# RockChip_RK3588 register map
Vendor: RockChip Electronics Co., Ltd.; Series: RK3588; File version: 0.1
Registers are 32-bit, read-write, no defined reset value unless marked. A register's access mark holds for its fields unless they carry their own. Offsets are from the block's base; [hi:lo] are bit positions; {n}, {i} and the like mark numbered series; 'fields as' and 'values as' point back to an identical list.

## CRU (part 5 of 6)
Base 0xFD7C0000
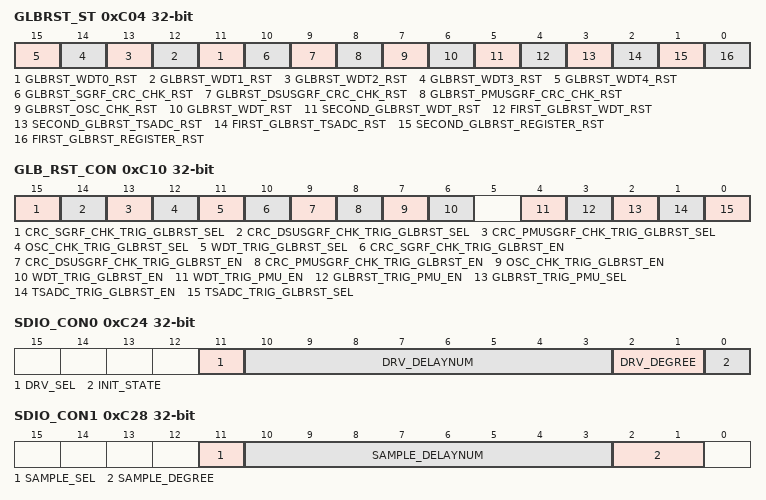
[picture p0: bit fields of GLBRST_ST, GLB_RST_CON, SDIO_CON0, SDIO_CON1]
0xC04 GLBRST_ST — System control register
  [n+11] GLBRST_WDT{n}_RST (n=0..4) — glbrst_wdt{n}_rst If High, global reset by WDT{n}.
  [10] GLBRST_SGRF_CRC_CHK_RST — glbrst_sgrf_crc_chk_rst If High, global reset by SGRF_CRC check.
  [9] GLBRST_DSUSGRF_CRC_CHK_RST — glbrst_dsusgrf_crc_chk_rst If High, global reset by DSUSGRF_CRC check.
  [8] GLBRST_PMUSGRF_CRC_CHK_RST — glbrst_pmusgrf_crc_chk_rst If High, global reset by PMUSGRF_CRC check.
  [7] GLBRST_OSC_CHK_RST — glbrst_osc_chk_rst If High, global reset by OSC check.
  [6] GLBRST_WDT_RST — glbrst_wdt_rst If High, global reset by WDT. Check CRU_GLBRST_ST[15:11] for detail.
  [5] SECOND_GLBRST_WDT_RST — second_glbrst_wdt_rst If High, second global reset by WDT.
  [4] FIRST_GLBRST_WDT_RST — first_glbrst_wdt_rst If High, first global reset by WDT.
  [3] SECOND_GLBRST_TSADC_RST — second_glbrst_tsadc_rst If High, second global reset by TSADC.
  [2] FIRST_GLBRST_TSADC_RST — first_glbrst_tsadc_rst If High, first global reset by TSADC.
  [1] SECOND_GLBRST_REGISTER_RST — second_glbrst_register_rst If High, second global reset by register.
  [0] FIRST_GLBRST_REGISTER_RST — first_glbrst_register_rst If High, first global reset by register.
0xC08 GLB_SRST_FST_VALUE — System control register
  [15:0] GLB_SRSC_FIRST_VALUE — GLB_SRST_FST The first global software reset configuration value. Set 0xfdb9 enable.
0xC0C GLB_SRST_SND_VALUE — System control register
  [15:0] GLB_SRSC_SECOND_VALUE — GLB_SRST_SND The second global software reset configuration value. Set 0xeca8 enable.
0xC10 GLB_RST_CON — System control register
  [15] CRC_SGRF_CHK_TRIG_GLBRST_SEL
    1=FIRST (CRC_SGRF check trigger first global reset.); 0=SECOND (CRC_SGRF check trigger second global reset.)
  [14] CRC_DSUSGRF_CHK_TRIG_GLBRST_SEL
    1=FIRST (CRC_DSUSGRF check trigger first global reset.); 0=SECOND (CRC_DSUSGRF check trigger second global reset.)
  [13] CRC_PMUSGRF_CHK_TRIG_GLBRST_SEL
    1=FIRST (CRC_PMUSGRF check trigger first global reset.); 0=SECOND (CRC_PMUSGRF check trigger second global reset.)
  [12] OSC_CHK_TRIG_GLBRST_SEL
    1=FIRST (OSC check trigger first global reset.); 0=SECOND (OSC check trigger second global reset.)
  [11] WDT_TRIG_GLBRST_SEL
    1=FIRST (WDT trigger first global reset.); 0=SECOND (WDT trigger second global reset.)
  [10] CRC_SGRF_CHK_TRIG_GLBRST_EN
    1=ENABLE (Enable CRC_SGRF check trigger global reset.); 0=DISABLE (Disable CRC_SGRF check trigger global reset.)
  [9] CRC_DSUSGRF_CHK_TRIG_GLBRST_EN
    1=ENABLE (Enable CRC_DSUSGRF check trigger global reset.); 0=DISABLE (Disable CRC_DSUSGRF check trigger global reset.)
  [8] CRC_PMUSGRF_CHK_TRIG_GLBRST_EN
    1=ENABLE (Enable CRC_PMUSGRF check trigger global reset.); 0=DISABLE (Disable CRC_PMUSGRF check trigger global reset.)
  [7] OSC_CHK_TRIG_GLBRST_EN
    1=ENABLE (Enable OSC check trigger global reset.); 0=DISABLE (Disable OSC check trigger global reset.)
  [6] WDT_TRIG_GLBRST_EN
    1=ENABLE (Enable WDT trigger global reset.); 0=DISABLE (Disable WDT trigger global reset.)
  [4] WDT_TRIG_PMU_EN
    1=ENABLE (Enable wdt reset trigger pmu reset.); 0=DISABLE (Disable wdt reset trigger pmu reset.)
  [3] GLBRST_TRIG_PMU_EN
    1=ENABLE (Enable global reset trigger pmu reset.); 0=DISABLE (Disable global reset trigger pmu reset.)
  [2] GLBRST_TRIG_PMU_SEL
    1=FIRST (First global reset trigger pmu reset.); 0=SECOND (Second global reset trigger pmu reset.)
  [1] TSADC_TRIG_GLBRST_EN
    1=ENABLE (Enable tsadc trigger global reset.); 0=DISABLE (Disable tsadc trigger global reset.)
  [0] TSADC_TRIG_GLBRST_SEL
    1=FIRST (tsadc trigger first global reset.); 0=SECOND (tsadc trigger second global reset.)
0xC24 SDIO_CON0 — System control register
  [11] DRV_SEL — Selection for drive clock
    0=PHASE (Select clock delayed by phase shift); 1=PHASE_AND_DELAY (Select clock delayed by phase shift and delay line It can be modified when init_state=1 and should be stable when init_state=0.)
  [10:3] DRV_DELAYNUM — Delay element number configuration for drive clock. It can be modified when init_state=1 and should be stable when init_state=0.
  [2:1] DRV_DEGREE — Phase selection for drive clock. It can be modified when init_state=1 and should be stable when init_state=0.
    0=DEGREE_0; 1=DEGREE_90; 2=DEGREE_180; 3=DEGREE_270
  [0] INIT_STATE — Enable initialization for clock source. When init_state=1, the host clocks including drive clock and sample clock are inactive.
    0=DISABLE; 1=ENABLE
0xC28 SDIO_CON1 — System control register
  [11] SAMPLE_SEL — Selection for sample clock. It can be modified when init_state=1 and should be stable when init_state=0.
    0=PHASE (Select clock delayed by phase shift); 1=PHASE_AND_DELAY (Select clock delayed by phase shift and delay line)
  [10:3] SAMPLE_DELAYNUM — Delay element number configuration for sample clock. It can be modified when init_state=1 and should be stable when init_state=0.
  [2:1] SAMPLE_DEGREE — Phase selection for sample clock. It can be modified when init_state=1 and should be stable when init_state=0.
    0=DEGREE_0; 1=DEGREE_90; 2=DEGREE_180; 3=DEGREE_270
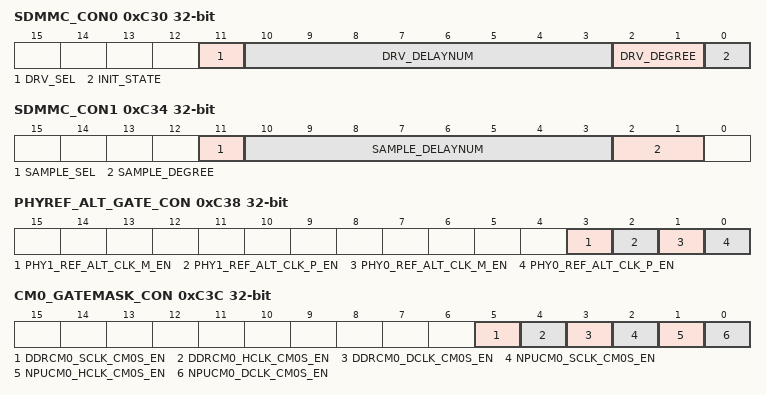
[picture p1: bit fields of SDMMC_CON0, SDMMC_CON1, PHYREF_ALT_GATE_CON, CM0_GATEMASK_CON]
0xC30 SDMMC_CON0 — System control register
  [11] DRV_SEL — Selection for drive clock. It can be modified when init_state=1 and should be stable when init_state=0.
    values as SDIO_CON1.SAMPLE_SEL
  [10:3] DRV_DELAYNUM — Delay element number configuration for drive clock. It can be modified when init_state=1 and should be stable when init_state=0.
  [2:1] DRV_DEGREE — Phase selection for drive clock. It can be modified when init_state=1 and should be stable when init_state=0.
    0=DEGREE_0; 1=DEGREE_90; 2=DEGREE_180; 3=DEGREE_270
  [0] INIT_STATE — Enable initialization for clock source. When init_state=1, the host clocks including drive clock and sample clock are inactive.
    0=DISABLE; 1=ENABLE
0xC34 SDMMC_CON1 — System control register
  fields as SDIO_CON1
0xC38 PHYREF_ALT_GATE_CON — System control register
  [all] fields
    1=DISABLE; 0=ENABLE
  [3] PHY1_REF_ALT_CLK_M_EN — phy1_ref_alt_clk_m clock gating control. When high, disable clock.
  [2] PHY1_REF_ALT_CLK_P_EN — phy1_ref_alt_clk_p clock gating control. When high, disable clock.
  [1] PHY0_REF_ALT_CLK_M_EN — phy0_ref_alt_clk_m clock gating control. When high, disable clock.
  [0] PHY0_REF_ALT_CLK_P_EN — phy0_ref_alt_clk_p clock gating control. When high, disable clock.
0xC3C CM0_GATEMASK_CON — System control register
  [all] fields
    1=DISABLE; 0=ENABLE
  [5] DDRCM0_SCLK_CM0S_EN — ddrcm0_sclk_cm0s clock gating control. When high, disable clock.
  [4] DDRCM0_HCLK_CM0S_EN — ddrcm0_hclk_cm0s clock gating control. When high, disable clock.
  [3] DDRCM0_DCLK_CM0S_EN — ddrcm0_dclk_cm0s clock gating control. When high, disable clock.
  [2] NPUCM0_SCLK_CM0S_EN — npucm0_sclk_cm0s clock gating control. When high, disable clock.
  [1] NPUCM0_HCLK_CM0S_EN — npucm0_hclk_cm0s clock gating control. When high, disable clock.
  [0] NPUCM0_DCLK_CM0S_EN — npucm0_dclk_cm0s clock gating control. When high, disable clock.
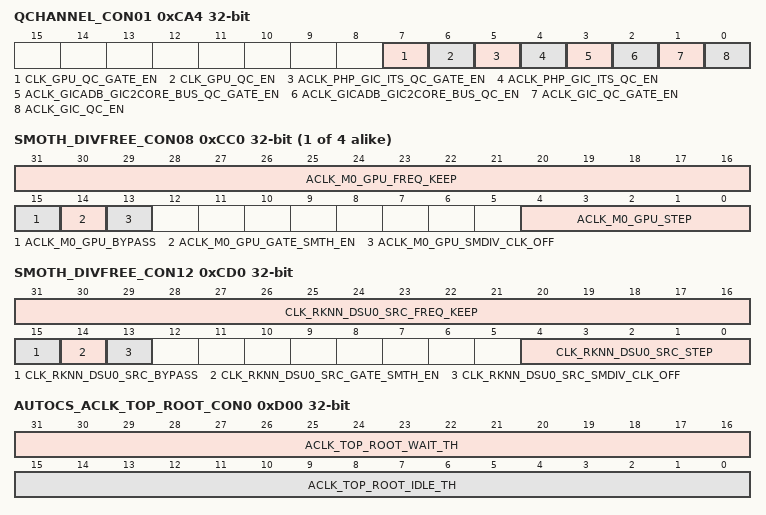
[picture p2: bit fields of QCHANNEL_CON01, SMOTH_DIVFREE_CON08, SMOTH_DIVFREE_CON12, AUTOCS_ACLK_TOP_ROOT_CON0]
0xCA4 QCHANNEL_CON01 — Qchannel control register 1
  [7] CLK_GPU_QC_GATE_EN — qc_gate_en
    1=DOC_BUG_ENABLE (Enable clk_gpu qchannel gate function.); 0=DOC_BUG_DISABLE (Disable clk_gpu qchannel gate function.)
  [6] CLK_GPU_QC_EN — qc_en
    1=DOC_BUG_ENABLE (Enable clk_gpu qchannel.); 0=DOC_BUG_DISABLE (Disable clk_gpu qchannel.)
  [5] ACLK_PHP_GIC_ITS_QC_GATE_EN — qc_gate_en
    1=DOC_BUG_ENABLE (Enable aclk_php_gic_its qchannel gate function.); 0=DOC_BUG_DISABLE (Disable aclk_php_gic_its qchannel gate function.)
  [4] ACLK_PHP_GIC_ITS_QC_EN — qc_en
    1=DOC_BUG_ENABLE (Enable aclk_php_gic_its qchannel.); 0=DOC_BUG_DISABLE (Disable aclk_php_gic_its qchannel.)
  [3] ACLK_GICADB_GIC2CORE_BUS_QC_GATE_EN — qc_gate_en
    1=DOC_BUG_ENABLE (Enable aclk_gicadb_gic2core_bus qchannel gate function.); 0=DOC_BUG_DISABLE (Disable aclk_gicadb_gic2core_bus qchannel gate function.)
  [2] ACLK_GICADB_GIC2CORE_BUS_QC_EN — qc_en
    1=DOC_BUG_ENABLE (Enable aclk_gicadb_gic2core_bus qchannel.); 0=DOC_BUG_DISABLE (Disable aclk_gicadb_gic2core_bus qchannel.)
  [1] ACLK_GIC_QC_GATE_EN — qc_gate_en
    1=DOC_BUG_ENABLE (Enable aclk_gic qchannel gate function.); 0=DOC_BUG_DISABLE (Disable aclk_gic qchannel gate function.)
  [0] ACLK_GIC_QC_EN — qc_en
    1=DOC_BUG_ENABLE (Enable aclk_gic qchannel.); 0=DOC_BUG_DISABLE (Disable aclk_gic qchannel.)
{0xCA0+4i} SMOTH_DIVFREE_CON{i:02} (i=8..11) — Smoothdiv control register
  [31:16] ACLK_M{i-8}_GPU_FREQ_KEEP — freq_keep Cycles to keep every step.
  [15] ACLK_M{i-8}_GPU_BYPASS — bypass Division signal bypass.
    1=BYPASS; 0=USE (Use Smoothdiv to control clock division.)
  [14] ACLK_M{i-8}_GPU_GATE_SMTH_EN — gate_smth_en If trigger smoothdiv function when clk been gated.
    1=ENABLE; 0=DISABLE
  [13] ACLK_M{i-8}_GPU_SMDIV_CLK_OFF — smdiv_clk_off Turn off smoothdiv module clk.
    1=TURN_OFF; 0=TURN_ON
  [4:0] ACLK_M{i-8}_GPU_STEP — step Step of div from 0x1f to setting configuration.
0xCD0 SMOTH_DIVFREE_CON12 — Smoothdiv control register
  [31:16] CLK_RKNN_DSU0_SRC_FREQ_KEEP — freq_keep Cycles to keep every step.
  [15] CLK_RKNN_DSU0_SRC_BYPASS — bypass Division signal bypass.
    1=BYPASS; 0=USE (Use Smoothdiv to control clock division.)
  [14] CLK_RKNN_DSU0_SRC_GATE_SMTH_EN — gate_smth_en If trigger smoothdiv function when clk been gated.
    1=ENABLE; 0=DISABLE
  [13] CLK_RKNN_DSU0_SRC_SMDIV_CLK_OFF — smdiv_clk_off Turn off smoothdiv module clk.
    1=TURN_OFF; 0=TURN_ON
  [4:0] CLK_RKNN_DSU0_SRC_STEP — step Step of div from 0x1f to setting configuration.
0xD00 AUTOCS_ACLK_TOP_ROOT_CON0 — Auto clock switch control register 0
  [31:16] ACLK_TOP_ROOT_WAIT_TH — wait_th. Wait time threshold, measured by original clk.
  [15:0] ACLK_TOP_ROOT_IDLE_TH — idle_th. Idle time threshold, measured by original clk.
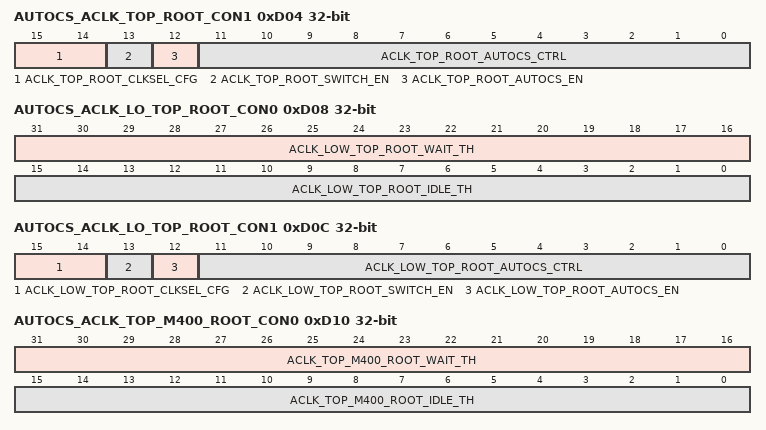
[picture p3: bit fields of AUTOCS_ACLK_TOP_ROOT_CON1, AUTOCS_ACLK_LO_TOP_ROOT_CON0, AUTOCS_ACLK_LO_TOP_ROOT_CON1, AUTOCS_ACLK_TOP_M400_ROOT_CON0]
0xD04 AUTOCS_ACLK_TOP_ROOT_CON1 — Auto clock switch control register 1
  [15:14] ACLK_TOP_ROOT_CLKSEL_CFG — clksel_cfg Auto switch clock selection.
    0=ORIGINAL_CLK; 1=XIN_OSC0_FUNC_DIV; 2=CLK_RTC_32K
  [13] ACLK_TOP_ROOT_SWITCH_EN — switch_en
    1=ENABLE (Enable aclk_top_root switched to lower frequency when module is inactive.); 0=DISABLE (Disable auto switch function.)
  [12] ACLK_TOP_ROOT_AUTOCS_EN — autocs_en
    1=ENABLE (Enable aclk_top_root switch to lower frequency.); 0=DISABLE
  [11:0] ACLK_TOP_ROOT_AUTOCS_CTRL — autocs_ctrl. Others: Reserved.
    0xFFF=ENABLE (Enable aclk_top_root switch to lower frequency.); 0=DISABLE
0xD08 AUTOCS_ACLK_LO_TOP_ROOT_CON0 — Auto clock switch control register 0
  [31:16] ACLK_LOW_TOP_ROOT_WAIT_TH — wait_th. Wait time threshold, measured by original clk.
  [15:0] ACLK_LOW_TOP_ROOT_IDLE_TH — idle_th. Idle time threshold, measured by original clk.
0xD0C AUTOCS_ACLK_LO_TOP_ROOT_CON1 — Auto clock switch control register 1
  [15:14] ACLK_LOW_TOP_ROOT_CLKSEL_CFG — clksel_cfg Auto switch clock selection.
    0=ORIGINAL_CLK; 1=XIN_OSC0_FUNC_DIV; 2=CLK_RTC_32K
  [13] ACLK_LOW_TOP_ROOT_SWITCH_EN — switch_en
    1=ENABLE (Enable aclk_low_top_root switched to lower frequency when module is inactive.); 0=DISABLE (Disable auto switch function.)
  [12] ACLK_LOW_TOP_ROOT_AUTOCS_EN — autocs_en
    1=ENABLE (Enable aclk_low_top_root switch to lower frequency.); 0=DISABLE
  [11:0] ACLK_LOW_TOP_ROOT_AUTOCS_CTRL — autocs_ctrl. Others: Reserved.
    0xFFF=ENABLE (Enable aclk_low_top_root switch to lower frequency.); 0=DISABLE
0xD10 AUTOCS_ACLK_TOP_M400_ROOT_CON0 — Auto clock switch control register 0
  [31:16] ACLK_TOP_M400_ROOT_WAIT_TH — wait_th. Wait time threshold, measured by original clk.
  [15:0] ACLK_TOP_M400_ROOT_IDLE_TH — idle_th. Idle time threshold, measured by original clk.
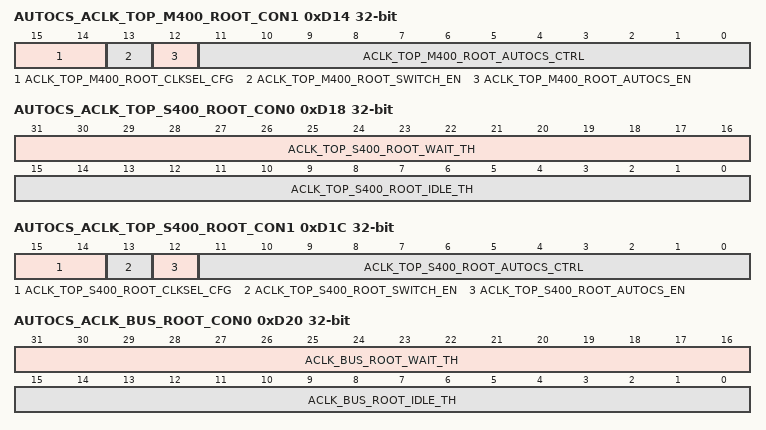
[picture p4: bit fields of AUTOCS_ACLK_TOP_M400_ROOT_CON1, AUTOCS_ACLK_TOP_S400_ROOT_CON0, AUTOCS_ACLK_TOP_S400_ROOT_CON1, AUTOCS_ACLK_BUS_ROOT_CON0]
0xD14 AUTOCS_ACLK_TOP_M400_ROOT_CON1 — Auto clock switch control register 1
  [15:14] ACLK_TOP_M400_ROOT_CLKSEL_CFG — clksel_cfg Auto switch clock selection.
    0=ORIGINAL_CLK; 1=XIN_OSC0_FUNC_DIV; 2=CLK_RTC_32K
  [13] ACLK_TOP_M400_ROOT_SWITCH_EN — switch_en
    1=ENABLE (Enable aclk_top_m400_root switched to lower frequency when module is inactive.); 0=DISABLE (Disable auto switch function.)
  [12] ACLK_TOP_M400_ROOT_AUTOCS_EN — autocs_en
    1=ENABLE (Enable aclk_top_m400_root switch to lower frequency.); 0=DISABLE
  [11:0] ACLK_TOP_M400_ROOT_AUTOCS_CTRL — autocs_ctrl. Others: Reserved.
    0xFFF=ENABLE (Enable aclk_top_m400_root switch to lower frequency.); 0=DISABLE
0xD18 AUTOCS_ACLK_TOP_S400_ROOT_CON0 — Auto clock switch control register 0
  [31:16] ACLK_TOP_S400_ROOT_WAIT_TH — wait_th. Wait time threshold, measured by original clk.
  [15:0] ACLK_TOP_S400_ROOT_IDLE_TH — idle_th. Idle time threshold, measured by original clk.
0xD1C AUTOCS_ACLK_TOP_S400_ROOT_CON1 — Auto clock switch control register 1
  [15:14] ACLK_TOP_S400_ROOT_CLKSEL_CFG — clksel_cfg Auto switch clock selection.
    0=ORIGINAL_CLK; 1=XIN_OSC0_FUNC_DIV; 2=CLK_RTC_32K
  [13] ACLK_TOP_S400_ROOT_SWITCH_EN — switch_en
    1=ENABLE (Enable aclk_top_s400_root switched to lower frequency when module is inactive.); 0=DISABLE (Disable auto switch function.)
  [12] ACLK_TOP_S400_ROOT_AUTOCS_EN — autocs_en
    1=ENABLE (Enable aclk_top_s400_root switch to lower frequency.); 0=DISABLE
  [11:0] ACLK_TOP_S400_ROOT_AUTOCS_CTRL — autocs_ctrl. Others: Reserved.
    0xFFF=ENABLE (Enable aclk_top_s400_root switch to lower frequency.); 0=DISABLE
0xD20 AUTOCS_ACLK_BUS_ROOT_CON0 — Auto clock switch control register 0
  [31:16] ACLK_BUS_ROOT_WAIT_TH — wait_th. Wait time threshold, measured by original clk.
  [15:0] ACLK_BUS_ROOT_IDLE_TH — idle_th. Idle time threshold, measured by original clk.
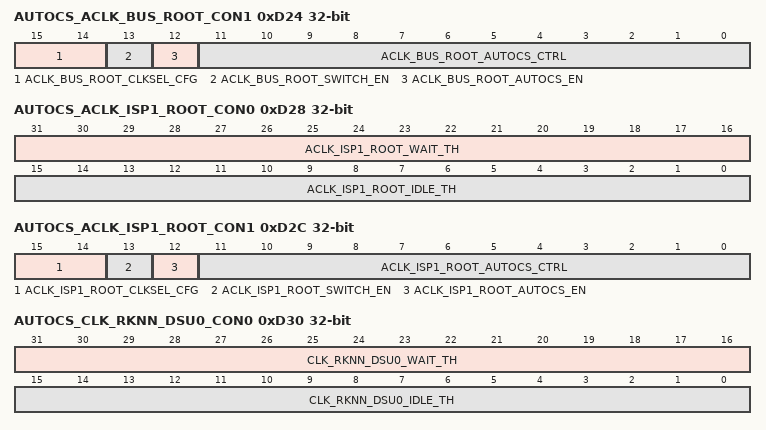
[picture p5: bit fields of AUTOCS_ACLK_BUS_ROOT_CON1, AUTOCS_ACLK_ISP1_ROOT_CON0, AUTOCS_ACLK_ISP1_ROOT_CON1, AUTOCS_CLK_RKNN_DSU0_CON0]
0xD24 AUTOCS_ACLK_BUS_ROOT_CON1 — Auto clock switch control register 1
  [15:14] ACLK_BUS_ROOT_CLKSEL_CFG — clksel_cfg Auto switch clock selection.
    0=ORIGINAL_CLK; 1=XIN_OSC0_FUNC_DIV; 2=CLK_RTC_32K
  [13] ACLK_BUS_ROOT_SWITCH_EN — switch_en
    1=ENABLE (Enable aclk_bus_root switched to lower frequency when module is inactive.); 0=DISABLE (Disable auto switch function.)
  [12] ACLK_BUS_ROOT_AUTOCS_EN — autocs_en
    1=ENABLE (Enable aclk_bus_root switch to lower frequency.); 0=DISABLE
  [11:0] ACLK_BUS_ROOT_AUTOCS_CTRL — autocs_ctrl. Others: Reserved.
    0xFFF=ENABLE (Enable aclk_bus_root switch to lower frequency.); 0=DISABLE
0xD28 AUTOCS_ACLK_ISP1_ROOT_CON0 — Auto clock switch control register 0
  [31:16] ACLK_ISP1_ROOT_WAIT_TH — wait_th. Wait time threshold, measured by original clk.
  [15:0] ACLK_ISP1_ROOT_IDLE_TH — idle_th. Idle time threshold, measured by original clk.
0xD2C AUTOCS_ACLK_ISP1_ROOT_CON1 — Auto clock switch control register 1
  [15:14] ACLK_ISP1_ROOT_CLKSEL_CFG — clksel_cfg Auto switch clock selection.
    0=ORIGINAL_CLK; 1=XIN_OSC0_FUNC_DIV; 2=CLK_RTC_32K
  [13] ACLK_ISP1_ROOT_SWITCH_EN — switch_en
    1=ENABLE (Enable aclk_isp1_root switched to lower frequency when module is inactive.); 0=DISABLE (Disable auto switch function.)
  [12] ACLK_ISP1_ROOT_AUTOCS_EN — autocs_en
    1=ENABLE (Enable aclk_isp1_root switch to lower frequency.); 0=DISABLE
  [11:0] ACLK_ISP1_ROOT_AUTOCS_CTRL — autocs_ctrl. Others: Reserved.
    0xFFF=ENABLE (Enable aclk_isp1_root switch to lower frequency.); 0=DISABLE
0xD30 AUTOCS_CLK_RKNN_DSU0_CON0 — Auto clock switch control register 0
  [31:16] CLK_RKNN_DSU0_WAIT_TH — wait_th. Wait time threshold, measured by original clk.
  [15:0] CLK_RKNN_DSU0_IDLE_TH — idle_th. Idle time threshold, measured by original clk.
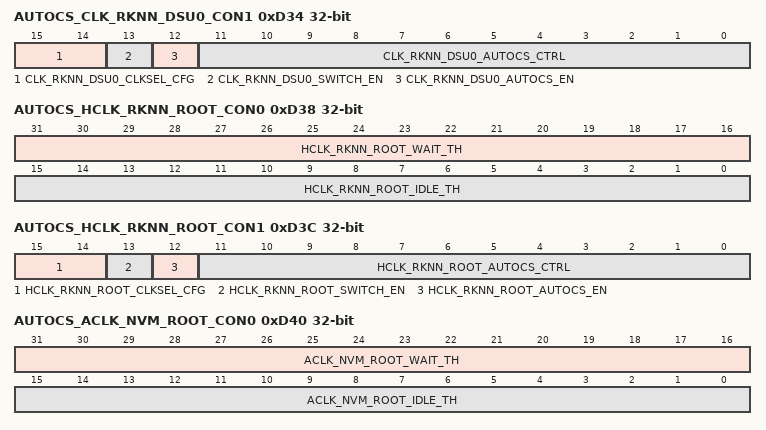
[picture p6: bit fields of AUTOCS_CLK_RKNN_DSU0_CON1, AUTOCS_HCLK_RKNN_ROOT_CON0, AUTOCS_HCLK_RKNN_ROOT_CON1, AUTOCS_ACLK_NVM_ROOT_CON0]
0xD34 AUTOCS_CLK_RKNN_DSU0_CON1 — Auto clock switch control register 1
  [15:14] CLK_RKNN_DSU0_CLKSEL_CFG — clksel_cfg Auto switch clock selection.
    0=ORIGINAL_CLK; 1=XIN_OSC0_FUNC_DIV; 2=CLK_RTC_32K
  [13] CLK_RKNN_DSU0_SWITCH_EN — switch_en
    1=ENABLE (Enable clk_rknn_dsu0 switched to lower frequency when module is inactive.); 0=DISABLE (Disable auto switch function.)
  [12] CLK_RKNN_DSU0_AUTOCS_EN — autocs_en
    1=ENABLE (Enable clk_rknn_dsu0 switch to lower frequency.); 0=DISABLE
  [11:0] CLK_RKNN_DSU0_AUTOCS_CTRL — autocs_ctrl. Others: Reserved.
    0xFFF=ENABLE (Enable clk_rknn_dsu0 switch to lower frequency.); 0=DISABLE
0xD38 AUTOCS_HCLK_RKNN_ROOT_CON0 — Auto clock switch control register 0
  [31:16] HCLK_RKNN_ROOT_WAIT_TH — wait_th. Wait time threshold, measured by original clk.
  [15:0] HCLK_RKNN_ROOT_IDLE_TH — idle_th. Idle time threshold, measured by original clk.
0xD3C AUTOCS_HCLK_RKNN_ROOT_CON1 — Auto clock switch control register 1
  [15:14] HCLK_RKNN_ROOT_CLKSEL_CFG — clksel_cfg Auto switch clock selection.
    0=ORIGINAL_CLK; 1=XIN_OSC0_FUNC_DIV; 2=CLK_RTC_32K
  [13] HCLK_RKNN_ROOT_SWITCH_EN — switch_en
    1=ENABLE (Enable hclk_rknn_root switched to lower frequency when module is inactive.); 0=DISABLE (Disable auto switch function.)
  [12] HCLK_RKNN_ROOT_AUTOCS_EN — autocs_en
    1=ENABLE (Enable hclk_rknn_root switch to lower frequency.); 0=DISABLE
  [11:0] HCLK_RKNN_ROOT_AUTOCS_CTRL — autocs_ctrl. Others: Reserved.
    0xFFF=ENABLE (Enable hclk_rknn_root switch to lower frequency.); 0=DISABLE
0xD40 AUTOCS_ACLK_NVM_ROOT_CON0 — Auto clock switch control register 0
  [31:16] ACLK_NVM_ROOT_WAIT_TH — wait_th. Wait time threshold, measured by original clk.
  [15:0] ACLK_NVM_ROOT_IDLE_TH — idle_th. Idle time threshold, measured by original clk.
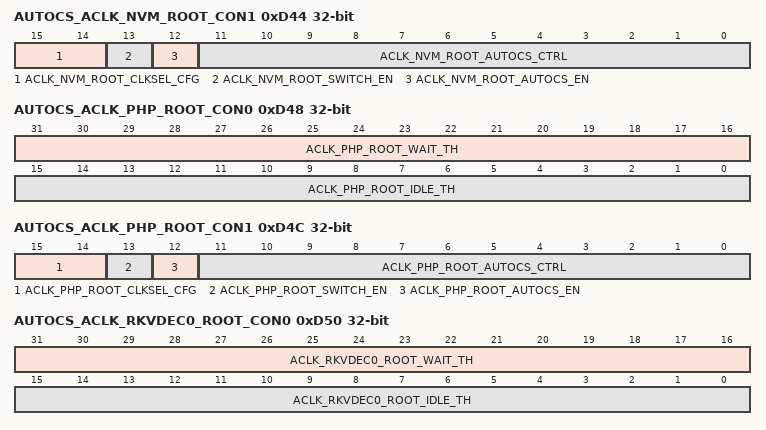
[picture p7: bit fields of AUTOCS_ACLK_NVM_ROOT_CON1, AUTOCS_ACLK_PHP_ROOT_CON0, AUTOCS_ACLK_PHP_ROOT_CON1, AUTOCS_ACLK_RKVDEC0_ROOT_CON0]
0xD44 AUTOCS_ACLK_NVM_ROOT_CON1 — Auto clock switch control register 1
  [15:14] ACLK_NVM_ROOT_CLKSEL_CFG — clksel_cfg Auto switch clock selection.
    0=ORIGINAL_CLK; 1=XIN_OSC0_FUNC_DIV; 2=CLK_RTC_32K
  [13] ACLK_NVM_ROOT_SWITCH_EN — switch_en
    1=ENABLE (Enable aclk_nvm_root switched to lower frequency when module is inactive.); 0=DISABLE (Disable auto switch function.)
  [12] ACLK_NVM_ROOT_AUTOCS_EN — autocs_en
    1=ENABLE (Enable aclk_nvm_root switch to lower frequency.); 0=DISABLE
  [11:0] ACLK_NVM_ROOT_AUTOCS_CTRL — autocs_ctrl. Others: Reserved.
    0xFFF=ENABLE (Enable aclk_nvm_root switch to lower frequency.); 0=DISABLE
0xD48 AUTOCS_ACLK_PHP_ROOT_CON0 — Auto clock switch control register 0
  [31:16] ACLK_PHP_ROOT_WAIT_TH — wait_th. Wait time threshold, measured by original clk.
  [15:0] ACLK_PHP_ROOT_IDLE_TH — idle_th. Idle time threshold, measured by original clk.
0xD4C AUTOCS_ACLK_PHP_ROOT_CON1 — Auto clock switch control register 1
  [15:14] ACLK_PHP_ROOT_CLKSEL_CFG — clksel_cfg Auto switch clock selection.
    0=ORIGINAL_CLK; 1=XIN_OSC0_FUNC_DIV; 2=CLK_RTC_32K
  [13] ACLK_PHP_ROOT_SWITCH_EN — switch_en
    1=ENABLE (Enable aclk_php_root switched to lower frequency when module is inactive.); 0=DISABLE (Disable auto switch function.)
  [12] ACLK_PHP_ROOT_AUTOCS_EN — autocs_en
    1=ENABLE (Enable aclk_php_root switch to lower frequency.); 0=DISABLE
  [11:0] ACLK_PHP_ROOT_AUTOCS_CTRL — autocs_ctrl. Others: Reserved.
    0xFFF=ENABLE (Enable aclk_php_root switch to lower frequency.); 0=DISABLE
0xD50 AUTOCS_ACLK_RKVDEC0_ROOT_CON0 — Auto clock switch control register 0
  [31:16] ACLK_RKVDEC0_ROOT_WAIT_TH — wait_th. Wait time threshold, measured by original clk.
  [15:0] ACLK_RKVDEC0_ROOT_IDLE_TH — idle_th. Idle time threshold, measured by original clk.
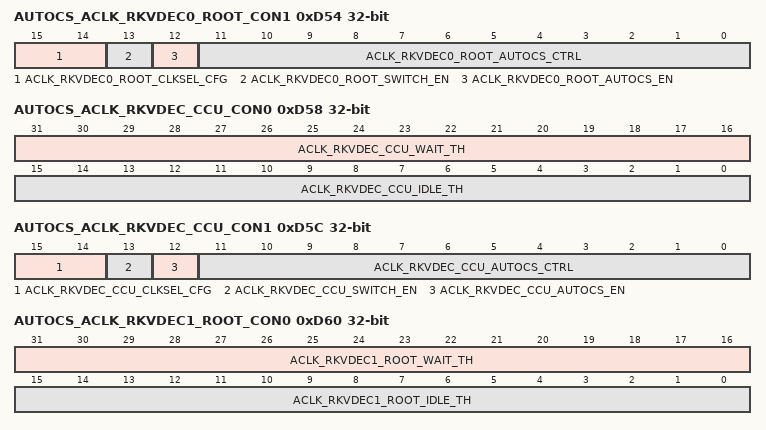
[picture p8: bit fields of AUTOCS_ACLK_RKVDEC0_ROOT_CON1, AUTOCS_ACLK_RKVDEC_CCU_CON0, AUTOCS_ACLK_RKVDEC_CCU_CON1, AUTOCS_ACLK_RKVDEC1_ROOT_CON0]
0xD54 AUTOCS_ACLK_RKVDEC0_ROOT_CON1 — Auto clock switch control register 1
  [15:14] ACLK_RKVDEC0_ROOT_CLKSEL_CFG — clksel_cfg Auto switch clock selection.
    0=ORIGINAL_CLK; 1=XIN_OSC0_FUNC_DIV; 2=CLK_RTC_32K
  [13] ACLK_RKVDEC0_ROOT_SWITCH_EN — switch_en
    1=ENABLE (Enable aclk_rkvdec0_root switched to lower frequency when module is inactive.); 0=DISABLE (Disable auto switch function.)
  [12] ACLK_RKVDEC0_ROOT_AUTOCS_EN — autocs_en
    1=ENABLE (Enable aclk_rkvdec0_root switch to lower frequency.); 0=DISABLE
  [11:0] ACLK_RKVDEC0_ROOT_AUTOCS_CTRL — autocs_ctrl. Others: Reserved.
    0xFFF=ENABLE (Enable aclk_rkvdec0_root switch to lower frequency.); 0=DISABLE
0xD58 AUTOCS_ACLK_RKVDEC_CCU_CON0 — Auto clock switch control register 0
  [31:16] ACLK_RKVDEC_CCU_WAIT_TH — wait_th. Wait time threshold, measured by original clk.
  [15:0] ACLK_RKVDEC_CCU_IDLE_TH — idle_th. Idle time threshold, measured by original clk.
0xD5C AUTOCS_ACLK_RKVDEC_CCU_CON1 — Auto clock switch control register 1
  [15:14] ACLK_RKVDEC_CCU_CLKSEL_CFG — clksel_cfg Auto switch clock selection.
    0=ORIGINAL_CLK; 1=XIN_OSC0_FUNC_DIV; 2=CLK_RTC_32K
  [13] ACLK_RKVDEC_CCU_SWITCH_EN — switch_en
    1=ENABLE (Enable aclk_rkvdec_ccu switched to lower frequency when module is inactive.); 0=DISABLE (Disable auto switch function.)
  [12] ACLK_RKVDEC_CCU_AUTOCS_EN — autocs_en
    1=ENABLE (Enable aclk_rkvdec_ccu switch to lower frequency.); 0=DISABLE
  [11:0] ACLK_RKVDEC_CCU_AUTOCS_CTRL — autocs_ctrl. Others: Reserved.
    0xFFF=ENABLE (Enable aclk_rkvdec_ccu switch to lower frequency.); 0=DISABLE
0xD60 AUTOCS_ACLK_RKVDEC1_ROOT_CON0 — Auto clock switch control register 0
  [31:16] ACLK_RKVDEC1_ROOT_WAIT_TH — wait_th. Wait time threshold, measured by original clk.
  [15:0] ACLK_RKVDEC1_ROOT_IDLE_TH — idle_th. Idle time threshold, measured by original clk.
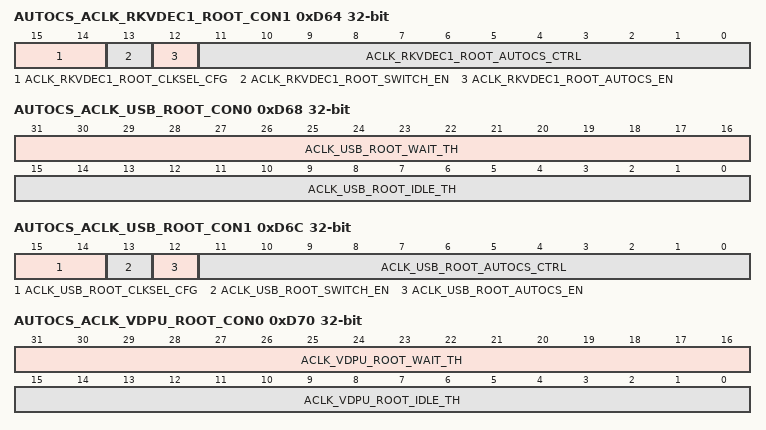
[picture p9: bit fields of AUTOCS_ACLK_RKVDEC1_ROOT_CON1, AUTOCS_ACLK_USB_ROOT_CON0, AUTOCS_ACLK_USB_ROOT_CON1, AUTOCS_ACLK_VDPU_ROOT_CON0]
0xD64 AUTOCS_ACLK_RKVDEC1_ROOT_CON1 — Auto clock switch control register 1
  [15:14] ACLK_RKVDEC1_ROOT_CLKSEL_CFG — clksel_cfg Auto switch clock selection.
    0=ORIGINAL_CLK; 1=XIN_OSC0_FUNC_DIV; 2=CLK_RTC_32K
  [13] ACLK_RKVDEC1_ROOT_SWITCH_EN — switch_en
    1=ENABLE (Enable aclk_rkvdec1_root switched to lower frequency when module is inactive.); 0=DISABLE (Disable auto switch function.)
  [12] ACLK_RKVDEC1_ROOT_AUTOCS_EN — autocs_en
    1=ENABLE (Enable aclk_rkvdec1_root switch to lower frequency.); 0=DISABLE
  [11:0] ACLK_RKVDEC1_ROOT_AUTOCS_CTRL — autocs_ctrl. Others: Reserved.
    0xFFF=ENABLE (Enable aclk_rkvdec1_root switch to lower frequency.); 0=DISABLE
0xD68 AUTOCS_ACLK_USB_ROOT_CON0 — Auto clock switch control register 0
  [31:16] ACLK_USB_ROOT_WAIT_TH — wait_th. Wait time threshold, measured by original clk.
  [15:0] ACLK_USB_ROOT_IDLE_TH — idle_th. Idle time threshold, measured by original clk.
0xD6C AUTOCS_ACLK_USB_ROOT_CON1 — Auto clock switch control register 1
  [15:14] ACLK_USB_ROOT_CLKSEL_CFG — clksel_cfg Auto switch clock selection.
    0=ORIGINAL_CLK; 1=XIN_OSC0_FUNC_DIV; 2=CLK_RTC_32K
  [13] ACLK_USB_ROOT_SWITCH_EN — switch_en
    1=ENABLE (Enable aclk_usb_root switched to lower frequency when module is inactive.); 0=DISABLE (Disable auto switch function.)
  [12] ACLK_USB_ROOT_AUTOCS_EN — autocs_en
    1=ENABLE (Enable aclk_usb_root switch to lower frequency.); 0=DISABLE
  [11:0] ACLK_USB_ROOT_AUTOCS_CTRL — autocs_ctrl. Others: Reserved.
    0xFFF=ENABLE (Enable aclk_usb_root switch to lower frequency.); 0=DISABLE
0xD70 AUTOCS_ACLK_VDPU_ROOT_CON0 — Auto clock switch control register 0
  [31:16] ACLK_VDPU_ROOT_WAIT_TH — wait_th. Wait time threshold, measured by original clk.
  [15:0] ACLK_VDPU_ROOT_IDLE_TH — idle_th. Idle time threshold, measured by original clk.
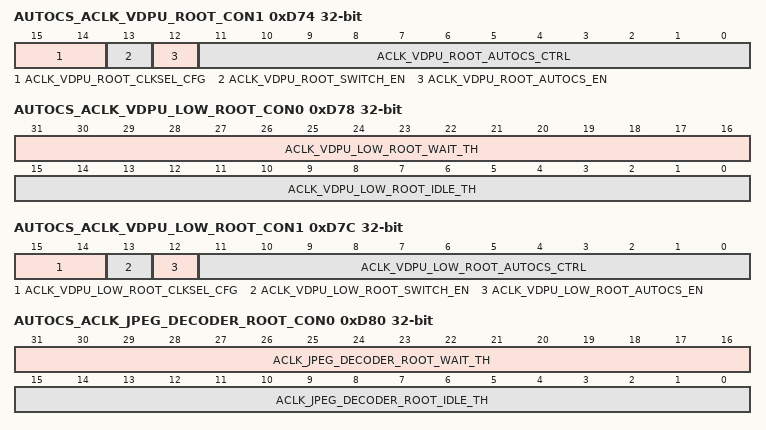
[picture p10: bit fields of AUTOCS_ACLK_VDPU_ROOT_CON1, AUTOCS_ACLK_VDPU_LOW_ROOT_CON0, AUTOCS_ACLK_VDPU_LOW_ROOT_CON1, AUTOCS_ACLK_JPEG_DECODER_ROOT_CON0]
0xD74 AUTOCS_ACLK_VDPU_ROOT_CON1 — Auto clock switch control register 1
  [15:14] ACLK_VDPU_ROOT_CLKSEL_CFG — clksel_cfg Auto switch clock selection.
    0=ORIGINAL_CLK; 1=XIN_OSC0_FUNC_DIV; 2=CLK_RTC_32K
  [13] ACLK_VDPU_ROOT_SWITCH_EN — switch_en
    1=ENABLE (Enable aclk_vdpu_root switched to lower frequency when module is inactive.); 0=DISABLE (Disable auto switch function.)
  [12] ACLK_VDPU_ROOT_AUTOCS_EN — autocs_en
    1=ENABLE (Enable aclk_vdpu_root switch to lower frequency.); 0=DISABLE
  [11:0] ACLK_VDPU_ROOT_AUTOCS_CTRL — autocs_ctrl. Others: Reserved.
    0xFFF=ENABLE (Enable aclk_vdpu_root switch to lower frequency.); 0=DISABLE
0xD78 AUTOCS_ACLK_VDPU_LOW_ROOT_CON0 — Auto clock switch control register 0
  [31:16] ACLK_VDPU_LOW_ROOT_WAIT_TH — wait_th. Wait time threshold, measured by original clk.
  [15:0] ACLK_VDPU_LOW_ROOT_IDLE_TH — idle_th. Idle time threshold, measured by original clk.
0xD7C AUTOCS_ACLK_VDPU_LOW_ROOT_CON1 — Auto clock switch control register 1
  [15:14] ACLK_VDPU_LOW_ROOT_CLKSEL_CFG — clksel_cfg Auto switch clock selection.
    0=ORIGINAL_CLK; 1=XIN_OSC0_FUNC_DIV; 2=CLK_RTC_32K
  [13] ACLK_VDPU_LOW_ROOT_SWITCH_EN — switch_en
    1=ENABLE (Enable aclk_vdpu_low_root switched to lower frequency when module is inactive.); 0=DISABLE (Disable auto switch function.)
  [12] ACLK_VDPU_LOW_ROOT_AUTOCS_EN — autocs_en
    1=ENABLE (Enable aclk_vdpu_low_root switch to lower frequency.); 0=DISABLE
  [11:0] ACLK_VDPU_LOW_ROOT_AUTOCS_CTRL — autocs_ctrl. Others: Reserved.
    0xFFF=ENABLE (Enable aclk_vdpu_low_root switch to lower frequency.); 0=DISABLE
0xD80 AUTOCS_ACLK_JPEG_DECODER_ROOT_CON0 — Auto clock switch control register 0
  [31:16] ACLK_JPEG_DECODER_ROOT_WAIT_TH — wait_th. Wait time threshold, measured by original clk.
  [15:0] ACLK_JPEG_DECODER_ROOT_IDLE_TH — idle_th. Idle time threshold, measured by original clk.
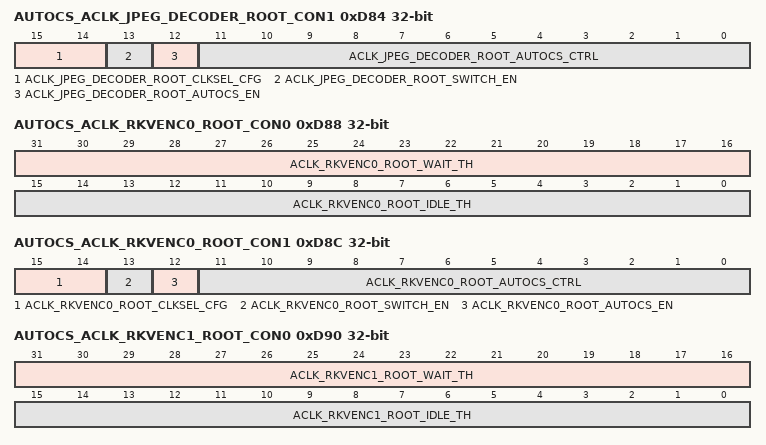
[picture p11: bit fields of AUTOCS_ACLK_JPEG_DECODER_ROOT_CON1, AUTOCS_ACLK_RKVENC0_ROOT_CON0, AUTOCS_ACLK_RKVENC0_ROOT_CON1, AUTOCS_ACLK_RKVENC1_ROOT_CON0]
0xD84 AUTOCS_ACLK_JPEG_DECODER_ROOT_CON1 — Auto clock switch control register 1
  [15:14] ACLK_JPEG_DECODER_ROOT_CLKSEL_CFG — clksel_cfg Auto switch clock selection.
    0=ORIGINAL_CLK; 1=XIN_OSC0_FUNC_DIV; 2=CLK_RTC_32K
  [13] ACLK_JPEG_DECODER_ROOT_SWITCH_EN — switch_en
    1=ENABLE (Enable aclk_jpeg_decoder_root switched to lower frequency when module is inactive.); 0=DISABLE (Disable auto switch function.)
  [12] ACLK_JPEG_DECODER_ROOT_AUTOCS_EN — autocs_en
    1=ENABLE (Enable aclk_jpeg_decoder_root switch to lower frequency.); 0=DISABLE
  [11:0] ACLK_JPEG_DECODER_ROOT_AUTOCS_CTRL — autocs_ctrl. Others: Reserved.
    0xFFF=ENABLE (Enable aclk_jpeg_decoder_root switch to lower frequency.); 0=DISABLE
0xD88 AUTOCS_ACLK_RKVENC0_ROOT_CON0 — Auto clock switch control register 0
  [31:16] ACLK_RKVENC0_ROOT_WAIT_TH — wait_th. Wait time threshold, measured by original clk.
  [15:0] ACLK_RKVENC0_ROOT_IDLE_TH — idle_th. Idle time threshold, measured by original clk.
0xD8C AUTOCS_ACLK_RKVENC0_ROOT_CON1 — Auto clock switch control register 1
  [15:14] ACLK_RKVENC0_ROOT_CLKSEL_CFG — clksel_cfg Auto switch clock selection.
    0=ORIGINAL_CLK; 1=XIN_OSC0_FUNC_DIV; 2=CLK_RTC_32K
  [13] ACLK_RKVENC0_ROOT_SWITCH_EN — switch_en
    1=ENABLE (Enable aclk_rkvenc0_root switched to lower frequency when module is inactive.); 0=DISABLE (Disable auto switch function.)
  [12] ACLK_RKVENC0_ROOT_AUTOCS_EN — autocs_en
    1=ENABLE (Enable aclk_rkvenc0_root switch to lower frequency.); 0=DISABLE
  [11:0] ACLK_RKVENC0_ROOT_AUTOCS_CTRL — autocs_ctrl. Others: Reserved.
    0xFFF=ENABLE (Enable aclk_rkvenc0_root switch to lower frequency.); 0=DISABLE
0xD90 AUTOCS_ACLK_RKVENC1_ROOT_CON0 — Auto clock switch control register 0
  [31:16] ACLK_RKVENC1_ROOT_WAIT_TH — wait_th. Wait time threshold, measured by original clk.
  [15:0] ACLK_RKVENC1_ROOT_IDLE_TH — idle_th. Idle time threshold, measured by original clk.
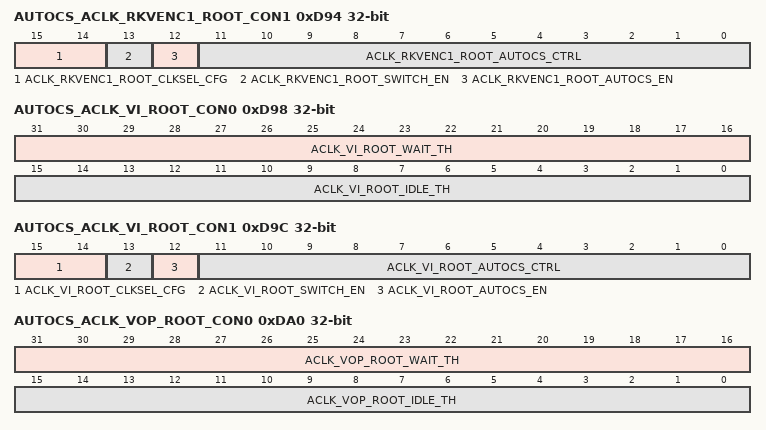
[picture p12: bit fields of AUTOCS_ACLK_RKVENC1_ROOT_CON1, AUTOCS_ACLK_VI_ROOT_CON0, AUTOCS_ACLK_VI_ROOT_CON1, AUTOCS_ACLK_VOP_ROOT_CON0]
0xD94 AUTOCS_ACLK_RKVENC1_ROOT_CON1 — Auto clock switch control register 1
  [15:14] ACLK_RKVENC1_ROOT_CLKSEL_CFG — clksel_cfg Auto switch clock selection.
    0=ORIGINAL_CLK; 1=XIN_OSC0_FUNC_DIV; 2=CLK_RTC_32K
  [13] ACLK_RKVENC1_ROOT_SWITCH_EN — switch_en
    1=ENABLE (Enable aclk_rkvenc1_root switched to lower frequency when module is inactive.); 0=DISABLE (Disable auto switch function.)
  [12] ACLK_RKVENC1_ROOT_AUTOCS_EN — autocs_en
    1=ENABLE (Enable aclk_rkvenc1_root switch to lower frequency.); 0=DISABLE
  [11:0] ACLK_RKVENC1_ROOT_AUTOCS_CTRL — autocs_ctrl. Others: Reserved.
    0xFFF=ENABLE (Enable aclk_rkvenc1_root switch to lower frequency.); 0=DISABLE
0xD98 AUTOCS_ACLK_VI_ROOT_CON0 — Auto clock switch control register 0
  [31:16] ACLK_VI_ROOT_WAIT_TH — wait_th. Wait time threshold, measured by original clk.
  [15:0] ACLK_VI_ROOT_IDLE_TH — idle_th. Idle time threshold, measured by original clk.
0xD9C AUTOCS_ACLK_VI_ROOT_CON1 — Auto clock switch control register 1
  [15:14] ACLK_VI_ROOT_CLKSEL_CFG — clksel_cfg Auto switch clock selection.
    0=ORIGINAL_CLK; 1=XIN_OSC0_FUNC_DIV; 2=CLK_RTC_32K
  [13] ACLK_VI_ROOT_SWITCH_EN — switch_en
    1=ENABLE (Enable aclk_vi_root switched to lower frequency when module is inactive.); 0=DISABLE (Disable auto switch function.)
  [12] ACLK_VI_ROOT_AUTOCS_EN — autocs_en
    1=ENABLE (Enable aclk_vi_root switch to lower frequency.); 0=DISABLE
  [11:0] ACLK_VI_ROOT_AUTOCS_CTRL — autocs_ctrl. Others: Reserved.
    0xFFF=ENABLE (Enable aclk_vi_root switch to lower frequency.); 0=DISABLE
0xDA0 AUTOCS_ACLK_VOP_ROOT_CON0 — Auto clock switch control register 0
  [31:16] ACLK_VOP_ROOT_WAIT_TH — wait_th. Wait time threshold, measured by original clk.
  [15:0] ACLK_VOP_ROOT_IDLE_TH — idle_th. Idle time threshold, measured by original clk.
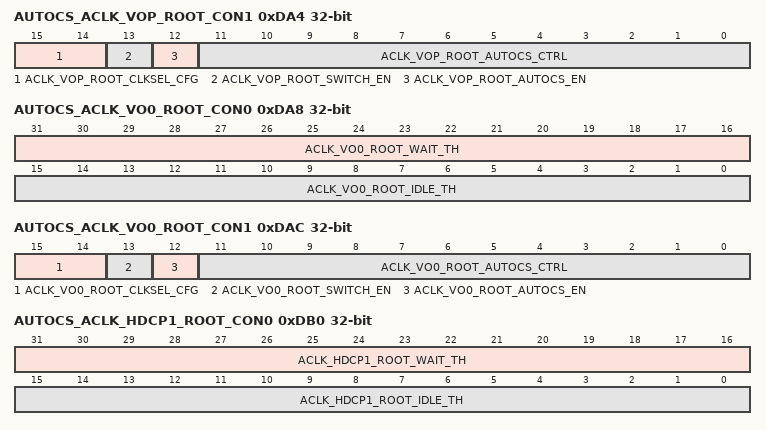
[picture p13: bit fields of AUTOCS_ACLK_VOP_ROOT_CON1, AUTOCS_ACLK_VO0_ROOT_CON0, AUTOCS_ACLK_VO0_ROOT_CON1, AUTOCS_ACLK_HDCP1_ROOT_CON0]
0xDA4 AUTOCS_ACLK_VOP_ROOT_CON1 — Auto clock switch control register 1
  [15:14] ACLK_VOP_ROOT_CLKSEL_CFG — clksel_cfg Auto switch clock selection.
    0=ORIGINAL_CLK; 1=XIN_OSC0_FUNC_DIV; 2=CLK_RTC_32K
  [13] ACLK_VOP_ROOT_SWITCH_EN — switch_en
    1=ENABLE (Enable aclk_vop_root switched to lower frequency when module is inactive.); 0=DISABLE (Disable auto switch function.)
  [12] ACLK_VOP_ROOT_AUTOCS_EN — autocs_en
    1=ENABLE (Enable aclk_vop_root switch to lower frequency.); 0=DISABLE
  [11:0] ACLK_VOP_ROOT_AUTOCS_CTRL — autocs_ctrl. Others: Reserved.
    0xFFF=ENABLE (Enable aclk_vop_root switch to lower frequency.); 0=DISABLE
0xDA8 AUTOCS_ACLK_VO0_ROOT_CON0 — Auto clock switch control register 0
  [31:16] ACLK_VO0_ROOT_WAIT_TH — wait_th. Wait time threshold, measured by original clk.
  [15:0] ACLK_VO0_ROOT_IDLE_TH — idle_th. Idle time threshold, measured by original clk.
0xDAC AUTOCS_ACLK_VO0_ROOT_CON1 — Auto clock switch control register 1
  [15:14] ACLK_VO0_ROOT_CLKSEL_CFG — clksel_cfg Auto switch clock selection.
    0=ORIGINAL_CLK; 1=XIN_OSC0_FUNC_DIV; 2=CLK_RTC_32K
  [13] ACLK_VO0_ROOT_SWITCH_EN — switch_en
    1=ENABLE (Enable aclk_vo0_root switched to lower frequency when module is inactive.); 0=DISABLE (Disable auto switch function.)
  [12] ACLK_VO0_ROOT_AUTOCS_EN — autocs_en
    1=ENABLE (Enable aclk_vo0_root switch to lower frequency.); 0=DISABLE
  [11:0] ACLK_VO0_ROOT_AUTOCS_CTRL — autocs_ctrl. Others: Reserved.
    0xFFF=ENABLE (Enable aclk_vo0_root switch to lower frequency.); 0=DISABLE
0xDB0 AUTOCS_ACLK_HDCP1_ROOT_CON0 — Auto clock switch control register 0
  [31:16] ACLK_HDCP1_ROOT_WAIT_TH — wait_th. Wait time threshold, measured by original clk.
  [15:0] ACLK_HDCP1_ROOT_IDLE_TH — idle_th. Idle time threshold, measured by original clk.
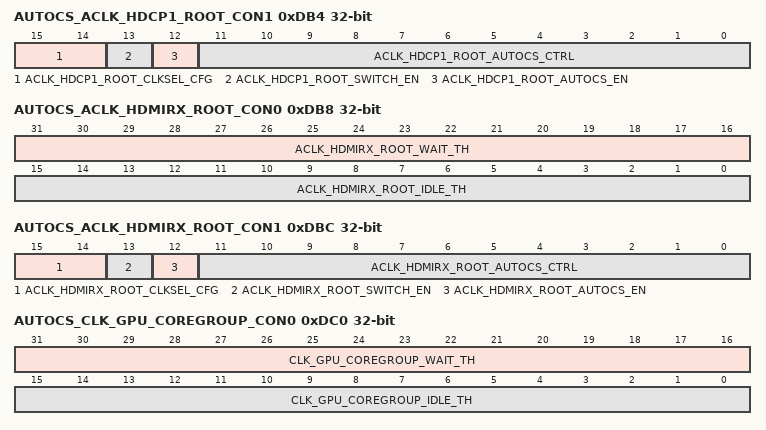
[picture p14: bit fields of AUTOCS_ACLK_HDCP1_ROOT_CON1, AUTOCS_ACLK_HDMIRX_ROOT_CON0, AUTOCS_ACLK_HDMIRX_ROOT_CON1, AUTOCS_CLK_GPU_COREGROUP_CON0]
0xDB4 AUTOCS_ACLK_HDCP1_ROOT_CON1 — Auto clock switch control register 1
  [15:14] ACLK_HDCP1_ROOT_CLKSEL_CFG — clksel_cfg Auto switch clock selection.
    0=ORIGINAL_CLK; 1=XIN_OSC0_FUNC_DIV; 2=CLK_RTC_32K
  [13] ACLK_HDCP1_ROOT_SWITCH_EN — switch_en
    1=ENABLE (Enable aclk_hdcp1_root switched to lower frequency when module is inactive.); 0=DISABLE (Disable auto switch function.)
  [12] ACLK_HDCP1_ROOT_AUTOCS_EN — autocs_en
    1=ENABLE (Enable aclk_hdcp1_root switch to lower frequency.); 0=DISABLE
  [11:0] ACLK_HDCP1_ROOT_AUTOCS_CTRL — autocs_ctrl. Others: Reserved.
    0xFFF=ENABLE (Enable aclk_hdcp1_root switch to lower frequency.); 0=DISABLE
0xDB8 AUTOCS_ACLK_HDMIRX_ROOT_CON0 — Auto clock switch control register 0
  [31:16] ACLK_HDMIRX_ROOT_WAIT_TH — wait_th. Wait time threshold, measured by original clk.
  [15:0] ACLK_HDMIRX_ROOT_IDLE_TH — idle_th. Idle time threshold, measured by original clk.
0xDBC AUTOCS_ACLK_HDMIRX_ROOT_CON1 — Auto clock switch control register 1
  [15:14] ACLK_HDMIRX_ROOT_CLKSEL_CFG — clksel_cfg Auto switch clock selection.
    0=ORIGINAL_CLK; 1=XIN_OSC0_FUNC_DIV; 2=CLK_RTC_32K
  [13] ACLK_HDMIRX_ROOT_SWITCH_EN — switch_en
    1=ENABLE (Enable aclk_hdmirx_root switched to lower frequency when module is inactive.); 0=DISABLE (Disable auto switch function.)
  [12] ACLK_HDMIRX_ROOT_AUTOCS_EN — autocs_en
    1=ENABLE (Enable aclk_hdmirx_root switch to lower frequency.); 0=DISABLE
  [11:0] ACLK_HDMIRX_ROOT_AUTOCS_CTRL — autocs_ctrl. Others: Reserved.
    0xFFF=ENABLE (Enable aclk_hdmirx_root switch to lower frequency.); 0=DISABLE
0xDC0 AUTOCS_CLK_GPU_COREGROUP_CON0 — Auto clock switch control register 0
  [31:16] CLK_GPU_COREGROUP_WAIT_TH — wait_th. Wait time threshold, measured by original clk.
  [15:0] CLK_GPU_COREGROUP_IDLE_TH — idle_th. Idle time threshold, measured by original clk.
0xDC4 AUTOCS_CLK_GPU_COREGROUP_CON1 — Auto clock switch control register 1
  [15:14] CLK_GPU_COREGROUP_CLKSEL_CFG — clksel_cfg Auto switch clock selection.
    0=ORIGINAL_CLK; 1=XIN_OSC0_FUNC_DIV; 2=CLK_RTC_32K
  [13] CLK_GPU_COREGROUP_SWITCH_EN — switch_en
    1=ENABLE (Enable clk_gpu_coregroup switched to lower frequency when module is inactive.); 0=DISABLE (Disable auto switch function.)
  [12] CLK_GPU_COREGROUP_AUTOCS_EN — autocs_en
    1=ENABLE (Enable clk_gpu_coregroup switch to lower frequency.); 0=DISABLE
  [11:0] CLK_GPU_COREGROUP_AUTOCS_CTRL — autocs_ctrl. Others: Reserved.
    0xFFF=ENABLE (Enable clk_gpu_coregroup switch to lower frequency.); 0=DISABLE
0xDE0 AUTOCS_ACLK_AV1_ROOT_CON0 — Auto clock switch control register 0
  [31:16] ACLK_AV1_ROOT_WAIT_TH — wait_th. Wait time threshold, measured by original clk.
  [15:0] ACLK_AV1_ROOT_IDLE_TH — idle_th. Idle time threshold, measured by original clk.
0xDE4 AUTOCS_ACLK_AV1_ROOT_CON1 — Auto clock switch control register 1
  [15:14] ACLK_AV1_ROOT_CLKSEL_CFG — clksel_cfg Auto switch clock selection.
    0=ORIGINAL_CLK; 1=XIN_OSC0_FUNC_DIV; 2=CLK_RTC_32K
  [13] ACLK_AV1_ROOT_SWITCH_EN — switch_en
    1=ENABLE (Enable aclk_av1_root switched to lower frequency when module is inactive.); 0=DISABLE (Disable auto switch function.)
  [12] ACLK_AV1_ROOT_AUTOCS_EN — autocs_en
    1=ENABLE (Enable aclk_av1_root switch to lower frequency.); 0=DISABLE
  [11:0] ACLK_AV1_ROOT_AUTOCS_CTRL — autocs_ctrl. Others: Reserved.
    0xFFF=ENABLE (Enable aclk_av1_root switch to lower frequency.); 0=DISABLE
0xDE8 AUTOCS_ACLK_CENTER_ROOT_CON0 — Auto clock switch control register 0
  [31:16] ACLK_CENTER_ROOT_WAIT_TH — wait_th. Wait time threshold, measured by original clk.
  [15:0] ACLK_CENTER_ROOT_IDLE_TH — idle_th. Idle time threshold, measured by original clk.
0xDEC AUTOCS_ACLK_CENTER_ROOT_CON1 — Auto clock switch control register 1
  [15:14] ACLK_CENTER_ROOT_CLKSEL_CFG — clksel_cfg Auto switch clock selection.
    0=ORIGINAL_CLK; 1=XIN_OSC0_FUNC_DIV; 2=CLK_RTC_32K
  [13] ACLK_CENTER_ROOT_SWITCH_EN — switch_en
    1=ENABLE (Enable aclk_center_root switched to lower frequency when module is inactive.); 0=DISABLE (Disable auto switch function.)
  [12] ACLK_CENTER_ROOT_AUTOCS_EN — autocs_en
    1=ENABLE (Enable aclk_center_root switch to lower frequency.); 0=DISABLE
  [11:0] ACLK_CENTER_ROOT_AUTOCS_CTRL — autocs_ctrl. Others: Reserved.
    0xFFF=ENABLE (Enable aclk_center_root switch to lower frequency.); 0=DISABLE
0xDF0 AUTOCS_ACLK_CENTER_LOW_ROOT_CON0 — Auto clock switch control register 0
  [31:16] ACLK_CENTER_LOW_ROOT_WAIT_TH — wait_th. Wait time threshold, measured by original clk.
  [15:0] ACLK_CENTER_LOW_ROOT_IDLE_TH — idle_th. Idle time threshold, measured by original clk.
0xDF4 AUTOCS_ACLK_CENTER_LOW_ROOT_CON1 — Auto clock switch control register 1
  [15:14] ACLK_CENTER_LOW_ROOT_CLKSEL_CFG — clksel_cfg Auto switch clock selection.
    0=ORIGINAL_CLK; 1=XIN_OSC0_FUNC_DIV; 2=CLK_RTC_32K
  [13] ACLK_CENTER_LOW_ROOT_SWITCH_EN — switch_en
    1=ENABLE (Enable aclk_center_low_root switched to lower frequency when module is inactive.); 0=DISABLE (Disable auto switch function.)
  [12] ACLK_CENTER_LOW_ROOT_AUTOCS_EN — autocs_en
    1=ENABLE (Enable aclk_center_low_root switch to lower frequency.); 0=DISABLE
  [11:0] ACLK_CENTER_LOW_ROOT_AUTOCS_CTRL — autocs_ctrl. Others: Reserved.
    0xFFF=ENABLE (Enable aclk_center_low_root switch to lower frequency.); 0=DISABLE
0xDF8 AUTOCS_ACLK_CENTER_S400_ROOT_CON0 — Auto clock switch control register 0
  [31:16] ACLK_CENTER_S400_ROOT_WAIT_TH — wait_th. Wait time threshold, measured by original clk.
  [15:0] ACLK_CENTER_S400_ROOT_IDLE_TH — idle_th. Idle time threshold, measured by original clk.
0xDFC AUTOCS_ACLK_CENTER_S400_ROOT_CON1 — Auto clock switch control register 1
  [15:14] ACLK_CENTER_S400_ROOT_CLKSEL_CFG — clksel_cfg Auto switch clock selection.
    0=ORIGINAL_CLK; 1=XIN_OSC0_FUNC_DIV; 2=CLK_RTC_32K
  [13] ACLK_CENTER_S400_ROOT_SWITCH_EN — switch_en
    1=ENABLE (Enable aclk_center_s400_root switched to lower frequency when module is inactive.); 0=DISABLE (Disable auto switch function.)
  [12] ACLK_CENTER_S400_ROOT_AUTOCS_EN — autocs_en
    1=ENABLE (Enable aclk_center_s400_root switch to lower frequency.); 0=DISABLE
  [11:0] ACLK_CENTER_S400_ROOT_AUTOCS_CTRL — autocs_ctrl. Others: Reserved.
    0xFFF=ENABLE (Enable aclk_center_s400_root switch to lower frequency.); 0=DISABLE
0xE00 AUTOCS_ACLK_VO1USB_TOP_ROOT_CON0 — Auto clock switch control register 0
  [31:16] ACLK_VO1USB_TOP_ROOT_WAIT_TH — wait_th. Wait time threshold, measured by original clk.
  [15:0] ACLK_VO1USB_TOP_ROOT_IDLE_TH — idle_th. Idle time threshold, measured by original clk.
0xE04 AUTOCS_ACLK_VO1USB_TOP_ROOT_CON1 — Auto clock switch control register 1
  [15:14] ACLK_VO1USB_TOP_ROOT_CLKSEL_CFG — clksel_cfg Auto switch clock selection.
    0=ORIGINAL_CLK; 1=XIN_OSC0_FUNC_DIV; 2=CLK_RTC_32K
  [13] ACLK_VO1USB_TOP_ROOT_SWITCH_EN — switch_en
    1=ENABLE (Enable aclk_vo1usb_top_root switched to lower frequency when module is inactive.); 0=DISABLE (Disable auto switch function.)
  [12] ACLK_VO1USB_TOP_ROOT_AUTOCS_EN — autocs_en
    1=ENABLE (Enable aclk_vo1usb_top_root switch to lower frequency.); 0=DISABLE
  [11:0] ACLK_VO1USB_TOP_ROOT_AUTOCS_CTRL — autocs_ctrl. Others: Reserved.
    0xFFF=ENABLE (Enable aclk_vo1usb_top_root switch to lower frequency.); 0=DISABLE
0xE08 AUTOCS_ACLK_RGA3_ROOT_CON0 — Auto clock switch control register 0
  [31:16] ACLK_RGA3_ROOT_WAIT_TH — wait_th. Wait time threshold, measured by original clk.
  [15:0] ACLK_RGA3_ROOT_IDLE_TH — idle_th. Idle time threshold, measured by original clk.
